# PN74xxAU register map
File version: 2
CPU: CM0 r0p0, little endian, no MPU, no FPU, 2 interrupt priority bits
Registers are 32-bit, read-write, reset 0x0 unless marked. A register's access mark holds for its fields unless they carry their own. Offsets are from the block's base; [hi:lo] are bit positions.

## SPIM — SPI Master
Base 0x40034000
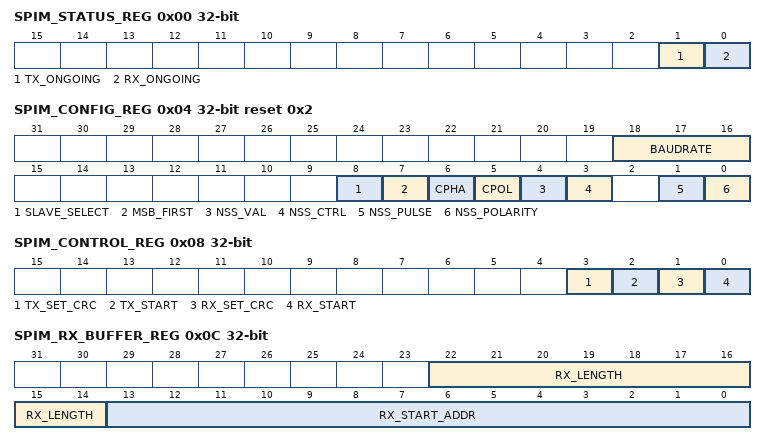
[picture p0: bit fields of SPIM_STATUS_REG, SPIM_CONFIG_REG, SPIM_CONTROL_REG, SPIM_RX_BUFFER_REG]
0x00 SPIM_STATUS_REG ro — SPIM Status
  [1] TX_ONGOING — 1 - TX buffer is currently in use by the HW.
  [0] RX_ONGOING — 1 - RX buffer is currently in use by the HW.
0x04 SPIM_CONFIG_REG reset 0x2 — SPIM Configuration of SPI Master
  [18:16] BAUDRATE — SCK frequency selction
  [8] SLAVE_SELECT — If set, Slave 1 is selected. If cleared, Slave 0 is selected.
  [7] MSB_FIRST — If set, MS bit of a byte is transmitted & received first
  [6] CPHA — 1 = Sampling of data occurs at even edges (2,4,6,...,16) of the SCK clock 0 = Sampling of data occurs at odd edges (1,3,5,...,15) of the SCK clock
  [5] CPOL — 1 = Active-low clocks selected. In idle state SCK is high. 0 = Active-high clocks selected. In idle state SCK is low
  [4] NSS_VAL — Value to ouput to nss if NSS_CTRL=1
  [3] NSS_CTRL — 1: override NSS value with NSS_VAL
  [1] NSS_PULSE — 1: a pulse on NSS is generated between 2 bytes
  [0] NSS_POLARITY — 0: NSS active low
0x08 SPIM_CONTROL_REG wo — SPIM RX/TX Control
  [3] TX_SET_CRC — Flag to init internal CRC to TX_CRC_INIT. Automatically returns to 0
  [2] TX_START — 1: Start Tx. Automatically returns to 0
  [1] RX_SET_CRC — Flag to init internal CRC to RX_CRC_INIT. Automatically returns to 0
  [0] RX_START — 1: Start Rx. Automatically returns to 0
0x0C SPIM_RX_BUFFER_REG — SPIM Configuration of RX buffer
  [22:14] RX_LENGTH — Size of Rx transfer
  [13:0] RX_START_ADDR — Byte start address of RX buffer
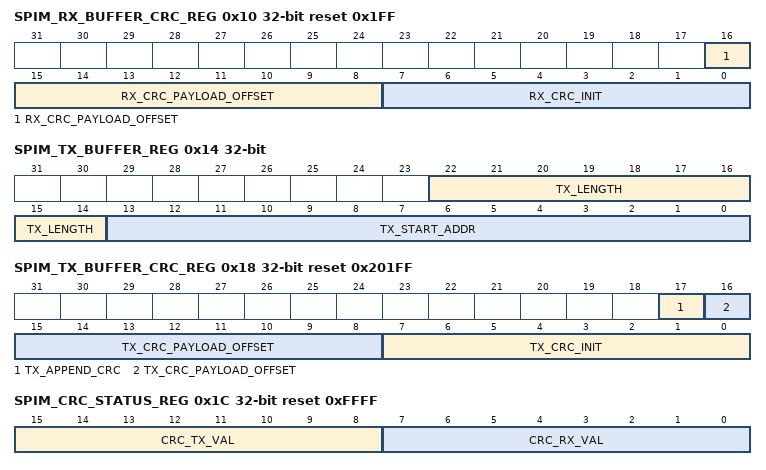
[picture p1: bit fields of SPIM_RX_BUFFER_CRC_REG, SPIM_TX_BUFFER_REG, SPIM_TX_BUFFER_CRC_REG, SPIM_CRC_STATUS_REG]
0x10 SPIM_RX_BUFFER_CRC_REG reset 0x1FF — SPIM Configuration of RX CRC
  [16:8] RX_CRC_PAYLOAD_OFFSET — Number of bytes to skip for CRC computation
  [7:0] RX_CRC_INIT — RX CRC init value. Only used if RX_SET_CRC is set
0x14 SPIM_TX_BUFFER_REG — SPIM Configuration of TX buffer
  [22:14] TX_LENGTH — Size of Tx transfer
  [13:0] TX_START_ADDR — Byte start address of TX buffer
0x18 SPIM_TX_BUFFER_CRC_REG reset 0x201FF — SPIM Configuration of TX CRC
  [17] TX_APPEND_CRC — 1: CRC is sent after transmission of TX_LENGTH bytes
  [16:8] TX_CRC_PAYLOAD_OFFSET — Number of bytes to skip for CRC computation
  [7:0] TX_CRC_INIT — TX CRC init value. Only used if TX_SET_CRC is set
0x1C SPIM_CRC_STATUS_REG ro reset 0xFFFF — SPIM Configuration of TX buffer
  [15:8] CRC_TX_VAL — Value of internal TX CRC
  [7:0] CRC_RX_VAL — Value of internal RX CRC
0x20 SPIM_WATERLEVEL_REG — SPIM Waterlevel
  [8:0] WATERLEVEL — Number of bytes received in incoming frame before triggering an interrupt (pre-empting EOR). If set to 0, this feature is disabled.
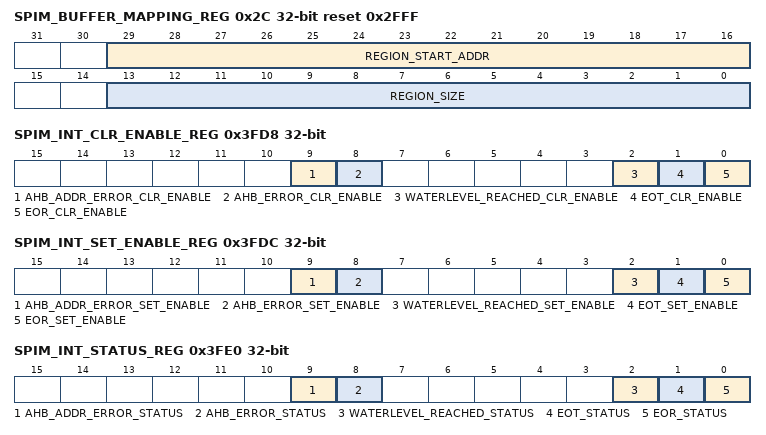
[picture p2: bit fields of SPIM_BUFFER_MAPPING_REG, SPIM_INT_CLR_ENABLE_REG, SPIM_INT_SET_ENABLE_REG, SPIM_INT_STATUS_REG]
0x2C SPIM_BUFFER_MAPPING_REG reset 0x2FFF — SPIM Buffer Mapping Register
  [29:16] REGION_START_ADDR — Start address of buffer region in system RAM
  [13:0] REGION_SIZE — Size of buffer region in system RAM
0x3FD8 SPIM_INT_CLR_ENABLE_REG wo — SPIM interrupt clear register
  [9] AHB_ADDR_ERROR_CLR_ENABLE — clear enable for AHB address overflow interrupt
  [8] AHB_ERROR_CLR_ENABLE — clear enable for AHB Slave error interrupt
  [2] WATERLEVEL_REACHED_CLR_ENABLE — Clear enable for waterlevel reached interrupt 0 - no effect
  [1] EOT_CLR_ENABLE — Clear enable for EOT interrupt
  [0] EOR_CLR_ENABLE — Clear enable for EOR interrupt
0x3FDC SPIM_INT_SET_ENABLE_REG wo — SPIM interrupt set register
  [9] AHB_ADDR_ERROR_SET_ENABLE — set enable for AHB address overflow interrupt
  [8] AHB_ERROR_SET_ENABLE — set enable for AHB Slave Error interrupt
  [2] WATERLEVEL_REACHED_SET_ENABLE — Set enable for waterlevel reached interrupt
  [1] EOT_SET_ENABLE — Set enable for EOT interrupt
  [0] EOR_SET_ENABLE — Set enable for EOR interrupt
0x3FE0 SPIM_INT_STATUS_REG ro — SPIM interrupt clear register
  [9] AHB_ADDR_ERROR_STATUS — AHB address overflow interrupt status
  [8] AHB_ERROR_STATUS — AHB Slave Error interrupt status
  [2] WATERLEVEL_REACHED_STATUS — Waterlevel reached interrupt status
  [1] EOT_STATUS — EOT interrupt status
  [0] EOR_STATUS — EOR interrupt status
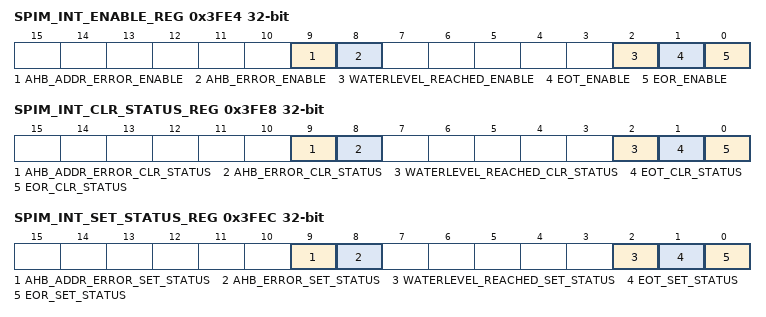
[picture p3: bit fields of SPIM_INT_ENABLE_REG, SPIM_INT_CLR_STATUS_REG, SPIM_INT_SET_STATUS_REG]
0x3FE4 SPIM_INT_ENABLE_REG ro — SPIM interrupt clear register
  [9] AHB_ADDR_ERROR_ENABLE — AHB address overflow interrupt enable
  [8] AHB_ERROR_ENABLE — AHB Slave Error interrupt enable
  [2] WATERLEVEL_REACHED_ENABLE — Waterlevel reached interrupt enable
  [1] EOT_ENABLE — EOT interrupt enable
  [0] EOR_ENABLE — EOR interrupt enable
0x3FE8 SPIM_INT_CLR_STATUS_REG wo — SPIM interrupt clear register
  [9] AHB_ADDR_ERROR_CLR_STATUS — clear AHB address overflow interrupt
  [8] AHB_ERROR_CLR_STATUS — clear AHB Slave Error interrupt
  [2] WATERLEVEL_REACHED_CLR_STATUS — Clear waterlevel reached interrupt
  [1] EOT_CLR_STATUS — Clear EOT interrupt
  [0] EOR_CLR_STATUS — Clear EOR interrupt
0x3FEC SPIM_INT_SET_STATUS_REG wo — SPIM interrupt clear register
  [9] AHB_ADDR_ERROR_SET_STATUS — set AHB address overflow interrupt
  [8] AHB_ERROR_SET_STATUS — set AHB Slave Error interrupt
  [2] WATERLEVEL_REACHED_SET_STATUS — Set waterlevel reached interrupt
  [1] EOT_SET_STATUS — Set EOT interrupt
  [0] EOR_SET_STATUS — Set EOR interrupt
